VERSION ""

NS_ :

BS_:

BU_: XXX

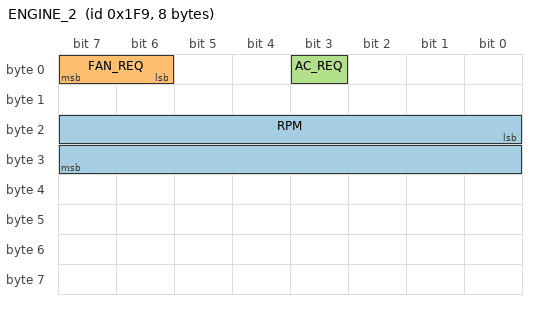
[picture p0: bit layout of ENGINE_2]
BO_ 505 ENGINE_2: 8 XXX
 SG_ RPM : 16|16@1+ (0.125,0) [0|45000] "R/min" XXX
 SG_ FAN_REQ : 6|2@1+ (1,0) [0|3] "" XXX
 SG_ AC_REQ : 3|1@1+ (1,0) [0|1] "" XXX

BO_ 573 ENGINE_1: 8 XXX
 SG_ Pedal_position : 8|8@1+ (0.392,0) [0|255] "%" XXX
 SG_ RPM : 24|16@1+ (3.15,0) [0|45000] "R/min" XXX

BO_ 640 SPEED: 8 XXX
 SG_ SPEED : 32|16@1+ (0.01,0) [0|45000] "" XXX

BO_ 861 BCM: 8 XXX

BO_ 1361 ENGINE_3: 8 XXX
 SG_ CLT : 0|8@1+ (1,-45) [-45|150] "" XXX

BO_ 1408 ENGINE_4: 8 XXX
 SG_ OIL_TEMP : 32|8@1+ (1,-40) [-40|150] "" XXX

BO_ 1477 MILEAGE: 8 XXX
